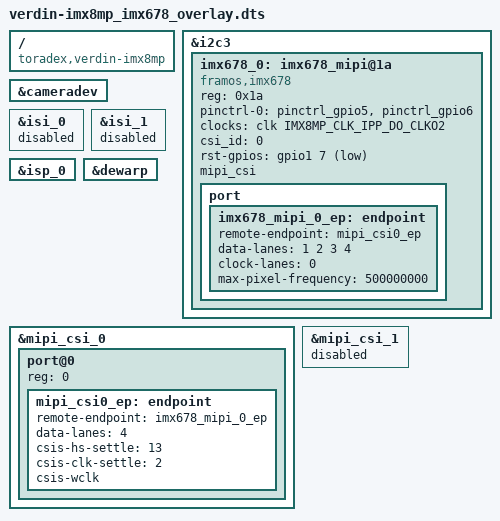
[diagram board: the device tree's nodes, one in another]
// SPDX-License-Identifier: GPL-2.0-or-later OR MIT

/dts-v1/;
/plugin/;

#include <dt-bindings/clock/imx8mp-clock.h>
#include <dt-bindings/gpio/gpio.h>

/ {
	compatible = "toradex,verdin-imx8mp";
};

#define CAMERA_I2C_MUX_BUS(x) (0x1E + x)

&i2c3 {
	status = "okay";

	imx678_0: imx678_mipi@1a {
		compatible = "framos,imx678";
		reg = <0x1a>;
		pinctrl-names = "default";
		pinctrl-0 = <&pinctrl_gpio5>, <&pinctrl_gpio6>;
		clocks = <&clk IMX8MP_CLK_IPP_DO_CLKO2>;
		clock-names = "csi_mclk";
		csi_id = <0>;
		rst-gpios = <&gpio1 7 GPIO_ACTIVE_LOW>;
		mipi_csi;
		status = "okay";

		port {
			imx678_mipi_0_ep: endpoint {
				remote-endpoint = <&mipi_csi0_ep>;
				data-lanes = <1 2 3 4>;
				clock-lanes = <0>;
				max-pixel-frequency = /bits/ 64 <500000000>;
			};
		};
	}; 
};

&cameradev {
	status = "okay";
};

&isi_0 {
	status = "disabled";
};

&isi_1 {
	status = "disabled";
};

&isp_0 {
	status = "okay";
};

&dewarp {
	status = "okay";
};

&mipi_csi_0 {
	#address-cells = <1>;
	#size-cells = <0>;
	status = "okay";

	port@0 {
		reg = <0>;
		mipi_csi0_ep: endpoint {
			remote-endpoint = <&imx678_mipi_0_ep>;
			data-lanes = <4>;
			csis-hs-settle = <13>;
			csis-clk-settle = <2>;
			csis-wclk;
		};
	};
};

&mipi_csi_1 {
	status = "disabled";
};
